# vpac_targetdb register map
Vendor: Texas Instruments
Registers are 32-bit, read-write, no defined reset value unless marked. A register's access mark holds for its fields unless they carry their own. Offsets are as the file gives them; [hi:lo] are bit positions; {n}, {i} and the like mark numbered series; 'fields as' and 'values as' point back to an identical list.

## VPAC (part 3 of 8) — Vision Pre-Processing Accelerator (VPAC)
0x44 YEE_MERGESEL — The Merge selects the output that is added to the target pixel.
  [0] yee_mergesel — The yee_mergesel selects either the sum of the LUT and edge sharpener output of the max of the absolute values from both. 0: selects the SUM. 1: elects the absolute value max.
0x44 exception_pend_clear — The Exception Logging Pending Clear Register allows to clear the pend signal.
  [0] pend_clr — Write a 1 to clear the exception pend signal.
0x44 exception_pend_clear — The Exception Logging Pending Clear Register allows to clear the pend signal.
  [0] pend_clr — Write a 1 to clear the exception pend signal.
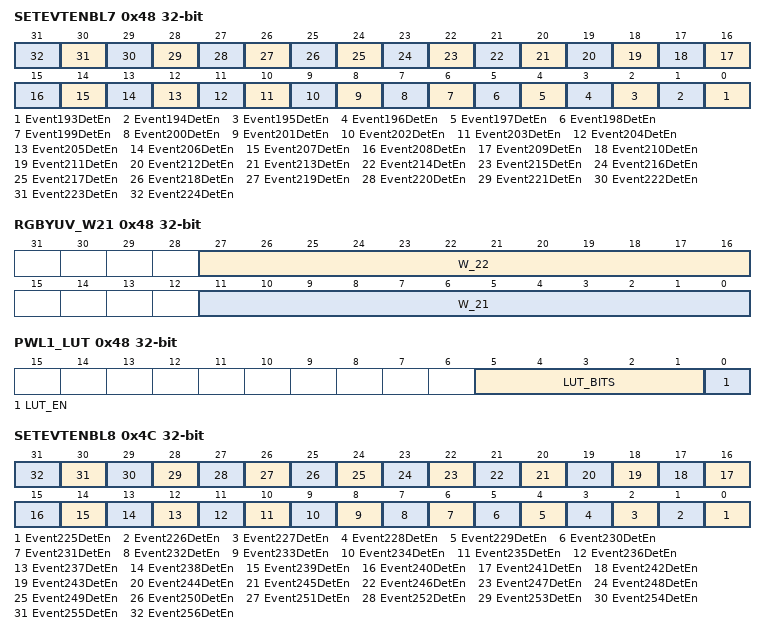
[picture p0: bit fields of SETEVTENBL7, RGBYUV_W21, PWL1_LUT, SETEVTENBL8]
0x48 SETEVTENBL7 — System event detection enable register 7 (if number of events > 192)
  [n-193] Event{n}DetEn (n=193..224) — Event({n}) Detection Enable
0x48 RD_BASE_L — Lower 32-bit of Input Frame Base Address
  [31:0] ADDR — Lower 32-bit of Read Base address of Input Frame Base Address. Must be 16-byte aligned so four LSB are coded to 0
0x48 RGBYUV_W21 access per field — Weight/Offset for Row2
  [27:16] W_22 rw — Weight W_22 : (S12 b)
  [11:0] W_21 rw — Weight W_21 : (S12 b)
0x48 PWL1_LUT access per field — Long frame PWL LUT configuration
  [5:1] LUT_BITS rw — LUT input bit depth, up to 24
  [0] LUT_EN rw — enable LUT based compression
0x48 H3A_AFCOEF1010 access per field — IIR filter coefficient data for SET 1.
  [11:0] COEFF10 rw — AF Engine IIR filter Coefficient #10 [Set 1] The range is signed -32 LTEQ value LTEQ 31 +63/64
0x48 YES_E_HAL — The Halo selects Halo reduction mode.
  [0] yes_e_hal — The yes_e_hal selects whether the 3x3 gradients is used to clip the target pixel. 0: Halo reduction off. 1: Halo reduction on.
0x4C SETEVTENBL8 — System event detection enable register 8 (if number of events > 224)
  [n-225] Event{n}DetEn (n=225..256) — Event({n}) Detection Enable
0x4C RD_420C_BASE_H — Higher 16-bit of Input Frame 420C Base Address
  [15:0] ADDR — Higher 16-bit of Input Frame Chroma Base Address in YUV420
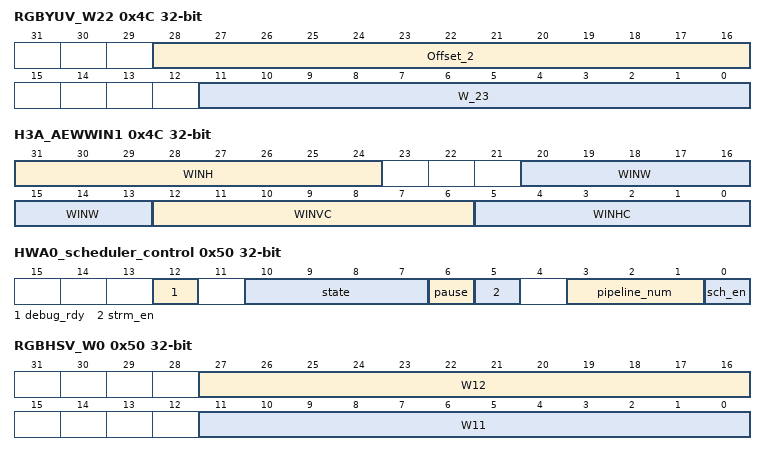
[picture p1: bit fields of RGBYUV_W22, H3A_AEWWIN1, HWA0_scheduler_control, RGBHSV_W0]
0x4C RGBYUV_W22 access per field — Weight/Offset for Row2
  [28:16] Offset_2 rw — Offset_2 : (S13b)
  [11:0] W_23 rw — Weight W_23 : (S12 b)
0x4C PWL1_LUTCLIP access per field — Long frame PWL LUT output clip value
  [15:0] LUTCLIP rw — LUT clip value
0x4C H3A_AEWWIN1 access per field — Configuration for AE/AWB Windows.
  [31:24] WINH rw — AE/AWB Engine Window Height This specifies the window height in an even number of pixels, the window height is the value plus 1 multiplied by 2 The final value can be from 2-512 [even] * This value is shadowed and latched on the rising edge of VSYNC
  [20:13] WINW rw — AE/AWB Engine Window Width This specifies the window width in an even number of pixels, the window width is the value plus 1 multiplied by 2 The minimum width is expected to be 8 pixels * This value is shadowed and latched on the rising edge of VSYNC
  [12:6] WINVC rw — AE/AWB Engine Vertical Window Count The number of windows in the vertical direction plus 1 The maximum number of vertical windows in a frame should not exceed 128 The value should be set to ensure that the bandwidth requirements and buffer size are not exceeded * This value is shadowed and latched on the rising edge of VSYNC
  [5:0] WINHC rw — AE/AWB Engine Horizontal Window Count The number of horizontal windows plus 1 The maximum number of horizontal windows is 35 plus 1 [36] The minimum number of windows should be 2 [valid range for the field is 1-35] * This value is shadowed and latched on the rising edge of VSYNC
0x4C YES_G_GAIN — The
  [7:0] yes_g_gain — The Gradient Gain
0x50 HWA0_scheduler_control access per field — Scheduler Control Register
  [12] debug_rdy rw — '0' -> HWA0 Scheduler resources must not be read during halted state. '1'-> HWA0 Scheduler resources are readable during halted state
  [10:7] state ro — Current state of HWA0 Scheduler
  [6] pause rw — '1' -> pause/suspend scheduler , '0' -> resume scheduler
  [5] strm_en rw — '1' -> Streaming input enable, '0' No streaming input
  [3:1] pipeline_num rw — Pipeline Number of HWA0 Scheduler
  [0] sch_en rw — scheduler enable; write '1' to enable scheduler
0x50 SETMSTID access per field — System Event Master ID
  [7:0] MASTID rw — HW Master ID for System Event module. Software may overwrite the value at any time, but this is only recommended for scenarios where top-level configuration errors result in a collision between HW master IDs
0x50 RD_420C_BASE_L — Lower 32-bit of Input Frame Chroma Base Address in YUV420
  [31:0] ADDR — Lower 32-bit of Read Base address of Input Frame Chroma Base Address in YUV420. Must be 16-byte aligned so four LSB are coded to 0
0x50 RGBHSV_W0 access per field — Weights 11/12 for V calculation
  [27:16] W12 rw — Weight W12 (Signed 12b)
  [11:0] W11 rw — Weight W11 (Signed 12b)
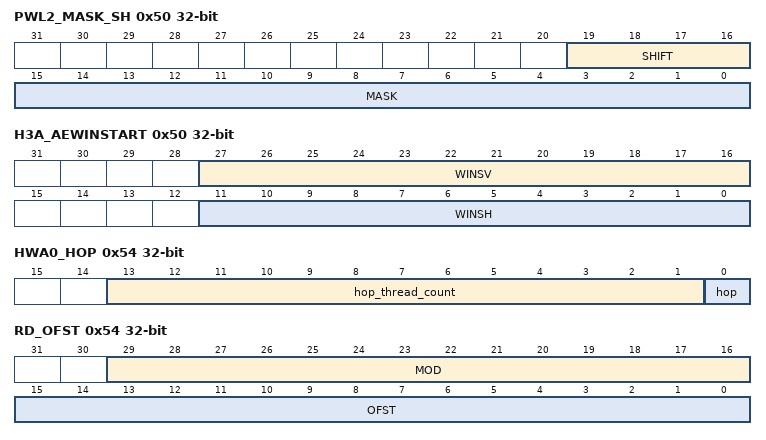
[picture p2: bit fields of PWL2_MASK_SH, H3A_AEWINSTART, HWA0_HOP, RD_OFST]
0x50 PWL2_MASK_SH access per field — Short frame PWL mask and shift values
  [19:16] SHIFT rw — number of right shift
  [15:0] MASK rw — mask bit pattern
0x50 H3A_AEWINSTART access per field — Start position for AE/AWB Windows.
  [27:16] WINSV rw — AE/AWB Engine Vertical Window Start Position Sets the first line for the first window Range 0-4095 * This value is shadowed and latched on the rising edge of VSYNC
  [11:0] WINSH rw — AE/AWB Engine Horizontal Window Start Position Sets the horizontal position for the first window on each line Range 0-4095 * This value is shadowed and latched on the rising edge of VSYNC
0x50 YES_E_GAIN — The
  [11:0] yes_e_gain — The Band-pass filter gain
0x54 HWA0_HOP — Scheduler HOP Control Register. Help in detecting eop within scheduler. Once configured, it counts task/channel starts and stops issuing further start. Specifically useful for Head of pipe dma scheduler .
  [13:1] hop_thread_count — Number of Task count for Head of pipe
  [0] hop — '1' -> Head of Pipe producer Sch , '0' -> No hop
0x54 RD_OFST — Defines the stride between rows for the Input Frame in bytes.
  [29:16] MOD — Sets the circular buffer size if circular buffering mode is used. The circular buffer is sized in terms of number of lines and has to be multiple of 2
  [15:0] OFST — Read frame line offset, must be 16-byte aligned so internally [3:0] bits are hard-wired zero. OFST is common for Luma and Chroma in YUV420 mode
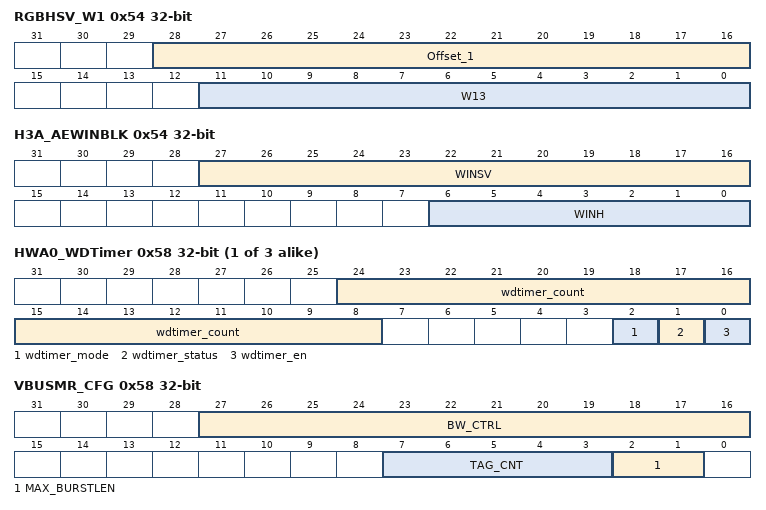
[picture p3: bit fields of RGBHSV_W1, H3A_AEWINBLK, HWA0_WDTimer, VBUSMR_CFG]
0x54 RGBHSV_W1 access per field — Weights13 and Offset_1 for V Calculation
  [28:16] Offset_1 rw — Offset_1 (Signed 13b)
  [11:0] W13 rw — Weight W13 (Signed 12b)
0x54 PWL2_EN access per field — Short frame PWL enable
  [0] ENABLE rw
0x54 H3A_AEWINBLK access per field — Start position and height for black line of AE/AWB Windows
  [27:16] WINSV rw — AE/AWB Engine Vertical Window Start Position for single black line of windows Sets the first line for the single black line of windows * This value is shadowed and latched on the rising edge of VSYNC Range 0-4095 Note that the horizontal start and the horizontal number of windows will be similar to the regular windows
  [6:0] WINH rw — AE/AWB Engine Window Height for the single black line of windows This specifies the window height in an even number of pixels, the window height is the value plus 1 multiplied by 2 The final value can be from 2-256 [even] * This value is shadowed and latched on the rising edge of VSYNC
0x54 YES_E_THR1 — The
  [15:0] yes_e_thr1 — The shrink threshold
{0x58+0xB4*i} HWA{i}_WDTimer access per field (i=0..2) — Watchdog timer control register
  [24:8] wdtimer_count ro — Current value of HWA{i} Scheduler watchdog timer count
  [2] wdtimer_mode rw — Watchdog timeout count '1' -> 128K , '0' -> 64K
  [1] wdtimer_status ro — HWA{i} Scheduler watchdog timer status '1' -> Timer Active '0' -> Timer Inactive (count is stable)
  [0] wdtimer_en rw — '1' -> activate watchdog timer for 64K VPAC/DMPAC cycles between task start and task done '0' -> Disable watchdog timer
0x58 VBUSMR_CFG — Control VBUSM Read Interface
  [27:16] BW_CTRL — Limits the mean bandwidth (computed over one block) that the LDC module can request for read from system memory. 0: The BW limiter is bypassed 1~4095: maximum number of bytes per cycle multiplied by 2^8. Examples: 1 : 1.17 MBytes/s @ 300 MHz 4095 : ~4.8 GBytes/s @ 300 Mhz
  [7:3] TAG_CNT — Limits the maximum number of outstanding LDC requests to TAG_CNT+1
  [2:1] MAX_BURSTLEN — Limits the maximum burst length that could be used by LDC. Each burst is of 16 bytes. HW also breaks the command at max burst size boundary. For K3 devices, it is best to keep burst size of 8 which command size of 128 bytes. 0: 16 1: 8 2: 4 3: 2
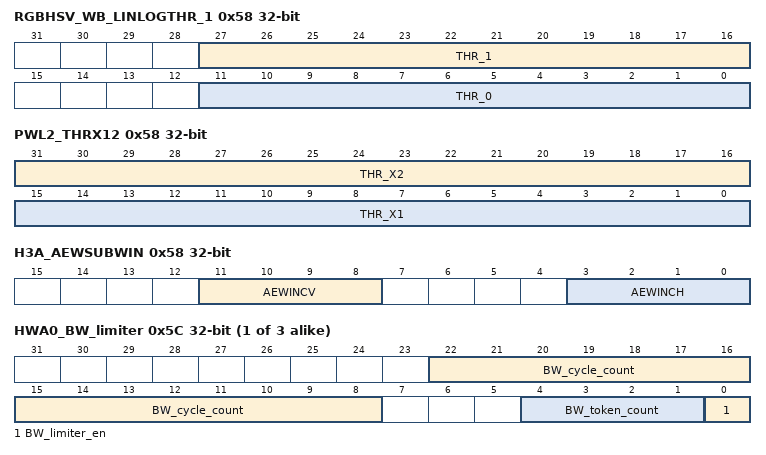
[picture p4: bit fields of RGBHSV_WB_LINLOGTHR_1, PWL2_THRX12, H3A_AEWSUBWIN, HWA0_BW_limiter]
0x58 RGBHSV_WB_LINLOGTHR_1 access per field — Dynamic WB Thr limit
  [27:16] THR_1 rw — THR_1 / G-Channel Thr (U 12b)
  [11:0] THR_0 rw — THR_0 / R-Channel Thr (U 12b)
0x58 PWL2_THRX12 — Short frame PWL threshold X1 and X2 - Unsigned
  [31:16] THR_X2 — threshold X2
  [15:0] THR_X1 — threshold X1
0x58 H3A_AEWSUBWIN access per field — Configuration for subsample data in AE/AWB window.
  [11:8] AEWINCV rw — AE/AWB Engine Vertical Sampling Point Increment Sets vertical distance between sub-samples within a window plus 1 multiplied by 2 The final range is 2-32 * This value is shadowed and latched on the rising edge of VSYNC
  [3:0] AEWINCH rw — AE/AWB Engine Horizontal Sampling Point Increment Sets horizontal distance between sub-samples within a window plus 1 multiplied by 2 The final range is 2-32 * This value is shadowed and latched on the rising edge of VSYNC
0x58 YES_E_THR2 — The
  [9:0] yes_e_thr2 — The clip threshold
{0x5C+0xB4*i} HWA{i}_BW_limiter (i=0..2) — Scheduler BW Control Register. Processing unit level BW control. Use DMA to eliminate peak system BW within processing units line/Block
  [22:8] BW_cycle_count — Average Cycle count between successive Task Start
  [4:1] BW_token_count — Max Token count to create average BW
  [0] BW_limiter_en — '1' -> Enable BW limiter function for HWA{i} sch, '0' --> Disable
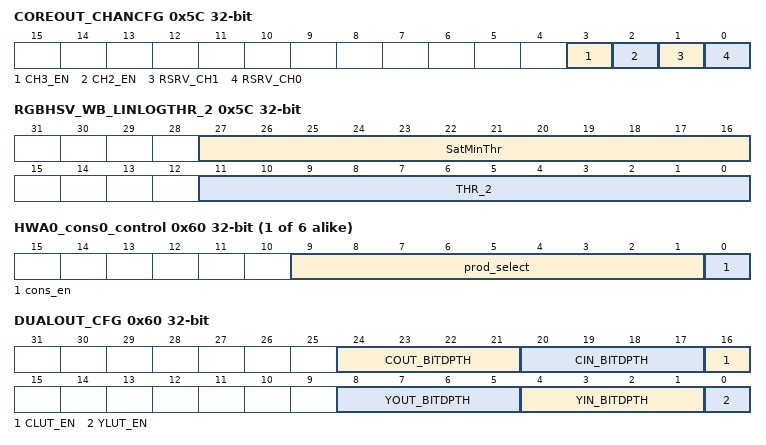
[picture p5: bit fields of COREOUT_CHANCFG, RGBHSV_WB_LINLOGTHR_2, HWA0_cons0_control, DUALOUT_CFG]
0x5C COREOUT_CHANCFG access per field — LDC Core to LSE output channel enable control
  [3] CH3_EN rw — Enable for LDC Core to LSE Channel_3 connection used for Chroma Dual output
  [2] CH2_EN rw — Enable for LDC Core to LSE Channel_2 connection used for Luma Dual output
  [1] RSRV_CH1 ro — Primary Chroma channel (LSE Channel_1) enable extracted from output data mode
  [0] RSRV_CH0 ro — Primary Luuma channel (LSE Channel_0) enable extracted from output data mode
0x5C RGBHSV_WB_LINLOGTHR_2 access per field — Dynamic WB Thr limit and SatMinThr
  [27:16] SatMinThr rw — Thr for comparing Min(RGB) limit
  [11:0] THR_2 rw — THR_2 / B-Channel Thr (U 12b)
0x5C PWL2_THRX3 access per field — Short frame PWL threshold X3 - Unsigned
  [15:0] THR_X3 rw — threshold X3
0x5C H3A_AEWBUFST access per field — SDRAM destination address for AE/AWB engine statistics
  [31:5] AEWBUFST rw — SDRAM destination address for AE/AWB engine statistics The start location in SDRAM for the AE/AWB statistics The 6 LSB are ignored, address should be on a 64-byte boundary This field can be altered even when the AE/AWB is busy Change will take place only for the next frame However, note that reading this register will always give the latest value
0x5C YES_G_OFT — The
  [9:0] yes_g_oft — The offset applied to the Gradient gain
{0x60+4i} HWA0_cons{i}_control (i=0..5) — Controlling consumer socket {i} for HWA0
  [9:1] prod_select — producer select for HWA0 cons socket {i}
  [0] cons_en — '1' -> Consumer socket {i} enable , '0' Disable
0x60 DUALOUT_CFG — Configuration for Dual Luma and Chroma channels and LUT
  [24:21] COUT_BITDPTH — Chroma Output Data Bit depth. Output clipped at 2^COUT_BITDPTH -1. Valid values 12-8
  [20:17] CIN_BITDPTH — Chroma Input Data Bit depth. Should same as YIN_BITDPTH. Valid values 12 to 8
  [16] CLUT_EN — Chroma LUT mapping enable. If disabled data is sent as it is bypassing LUT mapping
  [8:5] YOUT_BITDPTH — Luma Output Data Bit depth. Output clipped at 2^YOUT_BITDPTH -1. Valid values 12-8
  [4:1] YIN_BITDPTH — Luma Input Data Bit depth. Valid values 12 to 8
  [0] YLUT_EN — Luma LUT mapping enable. If disabled data is sent as it is bypassing LUT mapping
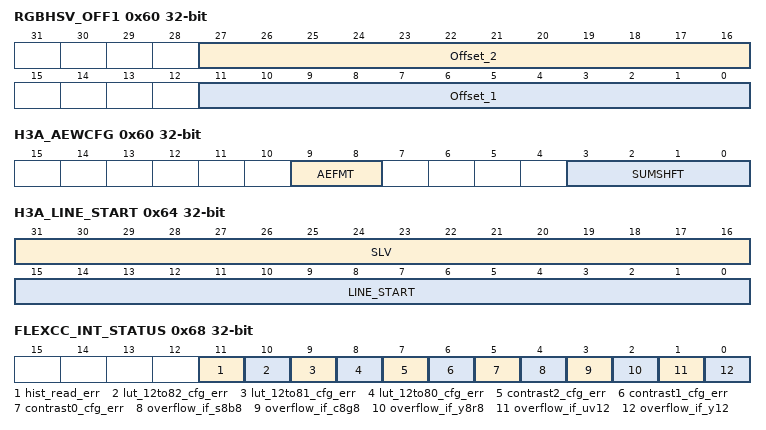
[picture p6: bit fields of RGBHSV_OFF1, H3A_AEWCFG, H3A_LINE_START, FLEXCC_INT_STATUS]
0x60 RGBHSV_OFF1 access per field — WB Offset for Saturation
  [27:16] Offset_2 rw — Offset_2 (U 12b)
  [11:0] Offset_1 rw — Offset-1 (U 12b)
{0x5C+4i} PWL2_THRY{i} access per field (i=1..3) — Short frame PWL threshold Y{i} - Unsigned
  [23:0] THR_Y{i} rw — threshold Y{i}
0x60 H3A_AEWCFG access per field — Configuration for AE/AWB
  [9:8] AEFMT rw — AE/AWB output format 0 = sum of squares 1 = min/max 2 = sum only; no sum of squares or min/max * This value is shadowed and latched on the rising edge of VSYNC
  [3:0] SUMSHFT rw — AE/AWB engine shift value for the accumulation of pixel values This bitfield sets the right shift value which is applied on the result of the pixel accumulation before it is stored in the packet The accumulation takes place on 26 bits which is enough for 10-bit data and a maximum widow size of 512 x 512 which results into the accumulation of 256 x 256 pixels of the same color The shift value shall be set such that the result fits on 16 bits SUMSHFT = right shift value Range: 0 -15 * This value is shadowed and latched on the rising edge of VSYNC
0x64 RGBHSV_OFF2 access per field — WB Offsets for Saturation
  [11:0] Offset_3 rw — Offset-3 (U 12b)
0x64 H3A_LINE_START — Line Framing Logic Register In certain cases the number of clock cycles between HD pulses will be greater than the line buffer included in the H3A module. The framing module prior to the line buffer enables to control the data which is input to the line buffer.
  [31:16] SLV — Start Line Vertical Specifies how many lines after the VD rising edge the real frame starts
  [15:0] LINE_START — Line Start The framing module uses the LINE_START bitfield to find the position of the first pixel to place into the line buffer Range: 0-65535
0x68 FLEXCC_INT_STATUS access per field — Status/clear register for flexcc interrupts
  [11] hist_read_err rw — status/clear for histogram memory, set when mem access has occurred to the first location but not to the last location during active frame implying that full histogram was not read . Write 1 to clear, write 0 has no effect
  [10] lut_12to82_cfg_err rw — status/clear for 12to8_2_lut cfg err, set when mem access occurs during active line when the LUT is enabled causing frame corruption. Write 1 to clear, write 0 has no effect
  [9] lut_12to81_cfg_err rw — status/clear for 12to8_1_lut cfg err, set when mem access occurs during active line when the LUT is enabled causing frame corruption. Write 1 to clear, write 0 has no effect
  [8] lut_12to80_cfg_err rw — status/clear for 12to8_0_lut cfg err, set when mem access occurs during active line when the LUT is enabled causing frame corruption. Write 1 to clear, write 0 has no effect
  [7] contrast2_cfg_err rw — status/clear for contrast2_lut cfg err, set when mem access occurs during active line when the LUT is enabled causing frame corruption. Write 1 to clear, write 0 has no effect
  [6] contrast1_cfg_err rw — status/clear for contrast1_lut cfg err, set when mem access occurs during active line when the LUT is enabled causing frame corruption. Write 1 to clear, write 0 has no effect
  [5] contrast0_cfg_err rw — status/clear for contrast0_lut cfg err, set when mem access occurs during active line when the LUT is enabled causing frame corruption. Write 1 to clear, write 0 has no effect
  [4] overflow_if_s8b8 rw — status/clear for overflow on s8b8 i/f, set when fifo overflows causing frame corruption. Write 1 to clear, write 0 has no effect
  [3] overflow_if_c8g8 rw — status/clear for overflow on c8g8 i/f, set when fifo overflows causing frame corruption. Write 1 to clear, write 0 has no effect
  [2] overflow_if_y8r8 rw — status/clear for overflow on y8r8 i/f, set when fifo overflows causing frame corruption. Write 1 to clear, write 0 has no effect
  [1] overflow_if_uv12 rw — status/clear for overflow on uv12 i/f, set when fifo overflows causing frame corruption. Write 1 to clear, write 0 has no effect
  [0] overflow_if_y12 rw — status/clear for overflow on y12 i/f, set when fifo overflows causing frame corruption. Write 1 to clear, write 0 has no effect
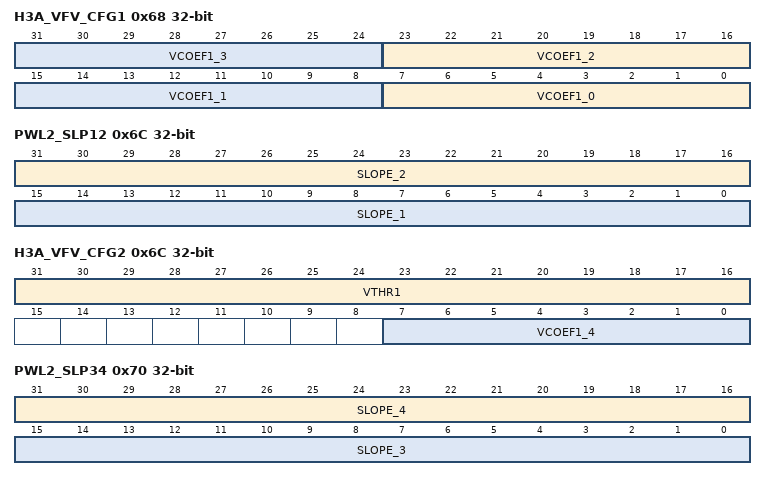
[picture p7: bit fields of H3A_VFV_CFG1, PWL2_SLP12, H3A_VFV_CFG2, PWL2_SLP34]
0x68 H3A_VFV_CFG1 — Vertical focus value configuration 1.
  [8n+7:8n] VCOEF1_{n} (n=0..3) — Vertical FV FIR 1 coefficient {n}
0x6C PWL2_SLP12 — Short frame PWL slope 1 and 2 - Unsigned
  [31:16] SLOPE_2, [15:0] SLOPE_1
0x6C H3A_VFV_CFG2 access per field — Vertical focus value configuration 2.
  [31:16] VTHR1 rw — Threshold for vertical FV FIR 1
  [7:0] VCOEF1_4 rw — Vertical FV FIR 1 coefficient 4
0x70 PWL2_SLP34 — Short frame PWL slope 3 and 4 - Unsigned
  [31:16] SLOPE_4, [15:0] SLOPE_3
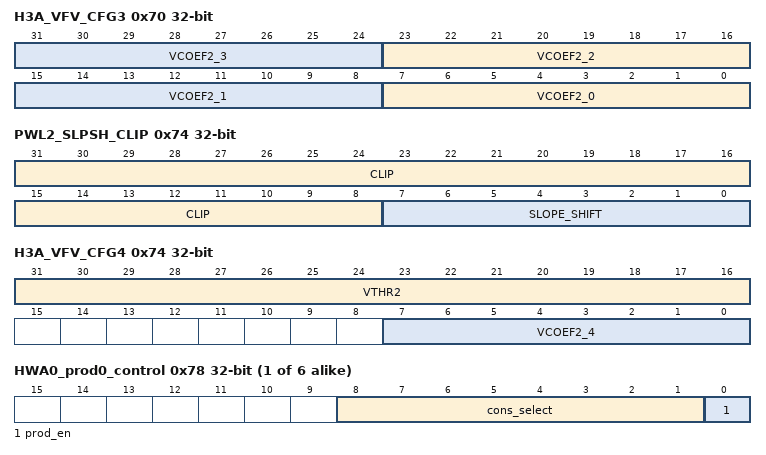
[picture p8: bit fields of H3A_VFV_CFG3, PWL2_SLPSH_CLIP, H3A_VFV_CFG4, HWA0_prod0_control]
0x70 H3A_VFV_CFG3 — Vertical focus value configuration 4.
  [8n+7:8n] VCOEF2_{n} (n=0..3) — Vertical FV FIR 2 coefficient {n}
0x74 PWL2_SLPSH_CLIP — Short frame PWL slope shift and clip
  [31:8] CLIP — clip value
  [7:0] SLOPE_SHIFT — shift value for slope, must not exceed decimal 33
0x74 H3A_VFV_CFG4 access per field — Vertical focus value configuration 4.
  [31:16] VTHR2 rw — Threshold for vertical FV FIR 2
  [7:0] VCOEF2_4 rw — Vertical FV FIR 2 coefficient 4
{0x78+0x14*i} HWA0_prod{i}_control (i=0..5) — Controlling producer socket{i} for HWA0
  [8:1] cons_select — consumer select for HWA0 prod socket {i}. Used in decrementing count of producer buffer
  [0] prod_en — '1' -> Producer socket 0 enable , '0' Disable
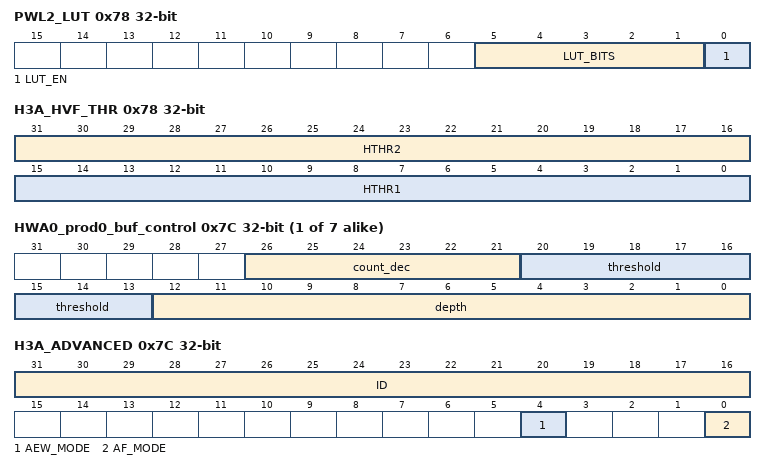
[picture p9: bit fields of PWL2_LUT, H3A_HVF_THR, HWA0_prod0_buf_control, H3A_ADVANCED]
0x78 PWL2_LUT access per field — Short frame PWL LUT configuration
  fields as PWL1_LUT
0x78 H3A_HVF_THR — Horizontal Focus Value Threshold
  [31:16] HTHR2 — Threshold for horizontal FV IIR 2
  [15:0] HTHR1 — Threshold for horizontal FV IIR 1
{0x7C+0x14*i} HWA0_prod{i}_buf_control (i=0..6) — Controlling producer socket{i} buffer for HWA0
  [26:21] count_dec — Count decrement value for prod count
  [20:13] threshold — Count threshold to generate pend for consumer
  [12:0] depth — Maximum number of producer buffer count
0x7C PWL2_LUTCLIP access per field — Short frame PWL LUT output clip value
  [15:0] LUTCLIP rw — LUT clip value
0x7C H3A_ADVANCED access per field — advanced setting register, NOT FOR TRM
  [31:16] ID ro — Below information should not be in TRM To access the other bitfields [AF_MODE/AEW_MODE], certain value should be written to this ID field first First, the ID is written to this field Second, the AF_MODE or/and AEW_MODE is written
  [4] AEW_MODE rw — This bit should not be included in TRM This bit is accesible only if ID is set to 0xDC00 AE/AWB engine custom mode [AVE2 mode] select
  [0] AF_MODE rw — AF engine mode Below information should not be included in TRM The effect of this bit changes based on the ID value If other value than 0xCA00 or 0xDC00 is set to ID, this field has no effect
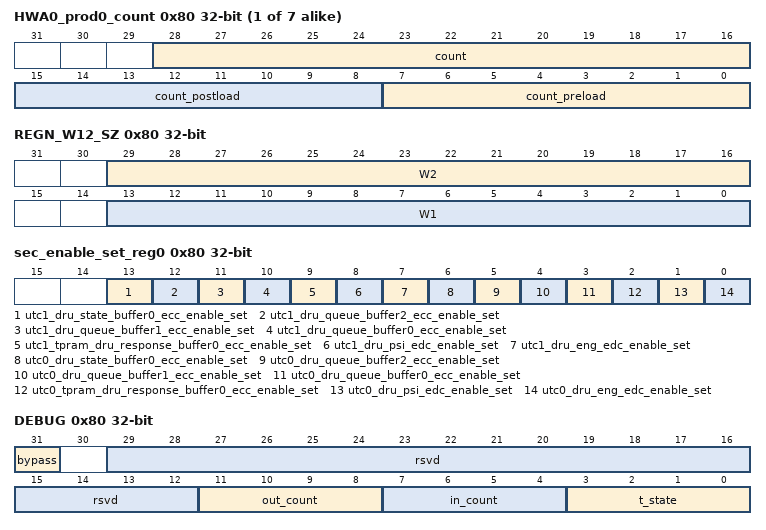
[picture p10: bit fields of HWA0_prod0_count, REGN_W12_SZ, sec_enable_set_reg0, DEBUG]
{0x80+0x14*i} HWA0_prod{i}_count access per field (i=0..6) — Defining count values for pre/post load for generating pend by HWA0 prod{i}
  [28:16] count ro — current count value
  [15:8] count_postload rw — count postload after producer max thread count reached
  [7:0] count_preload rw — count preload after scheduler start/init
0x80 sec_enable_set_reg0 — Interrupt Enable Set Register 0
  [13] utc1_dru_state_buffer0_ecc_enable_set — Interrupt Enable Set Register for utc1_dru_state_buffer0_ecc_pend
  [12] utc1_dru_queue_buffer2_ecc_enable_set — Interrupt Enable Set Register for utc1_dru_queue_buffer2_ecc_pend
  [11] utc1_dru_queue_buffer1_ecc_enable_set — Interrupt Enable Set Register for utc1_dru_queue_buffer1_ecc_pend
  [10] utc1_dru_queue_buffer0_ecc_enable_set — Interrupt Enable Set Register for utc1_dru_queue_buffer0_ecc_pend
  [9] utc1_tpram_dru_response_buffer0_ecc_enable_set — Interrupt Enable Set Register for utc1_tpram_dru_response_buffer0_ecc_pend
  [8] utc1_dru_psi_edc_enable_set — Interrupt Enable Set Register for utc1_dru_psi_edc_pend
  [7] utc1_dru_eng_edc_enable_set — Interrupt Enable Set Register for utc1_dru_eng_edc_pend
  [6] utc0_dru_state_buffer0_ecc_enable_set — Interrupt Enable Set Register for utc0_dru_state_buffer0_ecc_pend
  [5] utc0_dru_queue_buffer2_ecc_enable_set — Interrupt Enable Set Register for utc0_dru_queue_buffer2_ecc_pend
  [4] utc0_dru_queue_buffer1_ecc_enable_set — Interrupt Enable Set Register for utc0_dru_queue_buffer1_ecc_pend
  [3] utc0_dru_queue_buffer0_ecc_enable_set — Interrupt Enable Set Register for utc0_dru_queue_buffer0_ecc_pend
  [2] utc0_tpram_dru_response_buffer0_ecc_enable_set — Interrupt Enable Set Register for utc0_tpram_dru_response_buffer0_ecc_pend
  [1] utc0_dru_psi_edc_enable_set — Interrupt Enable Set Register for utc0_dru_psi_edc_pend
  [0] utc0_dru_eng_edc_enable_set — Interrupt Enable Set Register for utc0_dru_eng_edc_pend
0x80 sec_enable_set_reg0 — Interrupt Enable Set Register 0
  [n+8] meshmem_b{n}_p1_ramecc_enable_set (n=0..3) — Interrupt Enable Set Register for meshmem_b{n}_p1_ramecc_pend
  [n+4] meshmem_b{n}_p0_ramecc_enable_set (n=0..3) — Interrupt Enable Set Register for meshmem_b{n}_p0_ramecc_pend
  [3] dualc_lut_b1_ramecc_enable_set — Interrupt Enable Set Register for dualc_lut_b1_ramecc_pend
  [2] dualc_lut_b0_ramecc_enable_set — Interrupt Enable Set Register for dualc_lut_b0_ramecc_pend
  [1] dualy_lut_b1_ramecc_enable_set — Interrupt Enable Set Register for dualy_lut_b1_ramecc_pend
  [0] dualy_lut_b0_ramecc_enable_set — Interrupt Enable Set Register for dualy_lut_b0_ramecc_pend
0x80 REGN_W12_SZ — Horizontal slice width for Region division
  [29:16] W2 — Width of second horizontal slice. (Minium of 8 and must be even)
  [13:0] W1 — Width of first horizontal slice. (Minium of 8 and must be even)
0x80 sec_enable_set_reg0 — Interrupt Enable Set Register 0
  [31] fcc_lut1_ram1_ramecc_enable_set — Interrupt Enable Set Register for fcc_lut1_ram1_ramecc_pend
  [30] fcc_lut1_ram0_ramecc_enable_set — Interrupt Enable Set Register for fcc_lut1_ram0_ramecc_pend
  [29] fcc_lut0_ram1_ramecc_enable_set — Interrupt Enable Set Register for fcc_lut0_ram1_ramecc_pend
  [28] fcc_lut0_ram0_ramecc_enable_set — Interrupt Enable Set Register for fcc_lut0_ram0_ramecc_pend
  [27] fcc_cont_lut3_ram1_ramecc_enable_set — Interrupt Enable Set Register for fcc_cont_lut3_ram1_ramecc_pend
  [26] fcc_cont_lut3_ram0_ramecc_enable_set — Interrupt Enable Set Register for fcc_cont_lut3_ram0_ramecc_pend
  [25] fcc_cont_lut2_ram1_ramecc_enable_set — Interrupt Enable Set Register for fcc_cont_lut2_ram1_ramecc_pend
  [24] fcc_cont_lut2_ram0_ramecc_enable_set — Interrupt Enable Set Register for fcc_cont_lut2_ram0_ramecc_pend
  [23] fcc_cont_lut1_ram1_ramecc_enable_set — Interrupt Enable Set Register for fcc_cont_lut1_ram1_ramecc_pend
  [22] fcc_cont_lut1_ram0_ramecc_enable_set — Interrupt Enable Set Register for fcc_cont_lut1_ram0_ramecc_pend
  [21] fcc_hist_ram1_ramecc_enable_set — Interrupt Enable Set Register for fcc_hist_ram1_ramecc_pend
  [20] fcc_hist_ram0_ramecc_enable_set — Interrupt Enable Set Register for fcc_hist_ram0_ramecc_pend
  [n+12] stat_mem{n}_ramecc_enable_set (n=0..7) — Interrupt Enable Set Register for stat_mem{n}_ramecc_pend
  [11] h3a_lut_ram1_ramecc_enable_set — Interrupt Enable Set Register for h3a_lut_ram1_ramecc_pend
  [10] h3a_lut_ram0_ramecc_enable_set — Interrupt Enable Set Register for h3a_lut_ram0_ramecc_pend
  [9] lsc_ramecc_enable_set — Interrupt Enable Set Register for lsc_ramecc_pend
  [8] dpc_lut_ramecc_enable_set — Interrupt Enable Set Register for dpc_lut_ramecc_pend
  [7] wdr_lut_ram1_ramecc_enable_set — Interrupt Enable Set Register for wdr_lut_ram1_ramecc_pend
  [6] wdr_lut_ram0_ramecc_enable_set — Interrupt Enable Set Register for wdr_lut_ram0_ramecc_pend
  [5] lut1_ram1_ramecc_enable_set — Interrupt Enable Set Register for lut1_ram1_ramecc_pend
  [4] lut1_ram0_ramecc_enable_set — Interrupt Enable Set Register for lut1_ram0_ramecc_pend
  [3] lut2_ram1_ramecc_enable_set — Interrupt Enable Set Register for lut2_ram1_ramecc_pend
  [2] lut2_ram0_ramecc_enable_set — Interrupt Enable Set Register for lut2_ram0_ramecc_pend
  [1] lut3_ram1_ramecc_enable_set — Interrupt Enable Set Register for lut3_ram1_ramecc_pend
  [0] lut3_ram0_ramecc_enable_set — Interrupt Enable Set Register for lut3_ram0_ramecc_pend
0x80 VISS_DBG_CTL — Enable for VISS debug staus capture
  [1] PRTL_WR_EN — Enable to Capture Partial Write to any VISS end point
0x80 PWL2_OFF1 access per field — Short frame WB Offset 1
  [23:0] OFST00 rw — S24, WB Offset at pixel 00
0x80 DEBUG access per field
  [31] bypass rw — Bypass Mode When enabled output equals the input , namely C2_R0 input matrix
  [29:12] rsvd ro — Always read as 0. Writes have no affect
  [11:8] out_count ro — output free running counter , gets reset on start of line
  [7:4] in_count ro — input free running counter , gets reset on start of line
  [3:0] t_state ro — StateMachine State
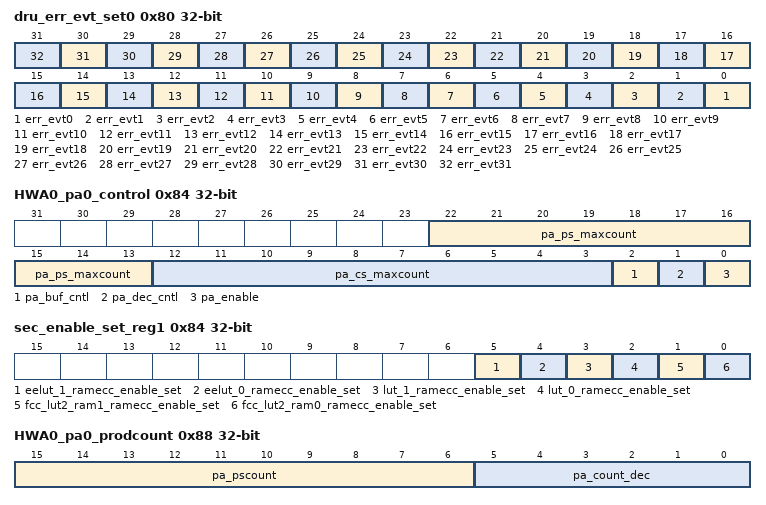
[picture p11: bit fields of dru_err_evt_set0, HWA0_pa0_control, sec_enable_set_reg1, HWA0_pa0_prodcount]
0x80 dru_err_evt_set0 wo — DRU Error Event Set Register
  [n] err_evt{n} (n=0..31) — Set the Error Event for channel {n}
0x80 dru_err_evt_set0 wo — DRU Error Event Set Register
  [n] err_evt{n} (n=0..63) — Set the Error Event for channel {n}
0x84 HWA0_pa0_control — control register to manage pattern adapter on HWA0 prod socket0
  [22:13] pa_ps_maxcount — destination count for pattern adaptation (N), M --> N
  [12:3] pa_cs_maxcount — source count for pattern adaptation (M), M --> N
  [2] pa_buf_cntl — '1' -> Apply threshold, count_preload and count_postload on pattern adapter count (use this only when pa_enable='1') '0' -> Apply threshold, count_preload and count_postload on prod count (same behavior as if no pattern adapter. Note when pa_enable='1' and pa_buf_cntl='0' threshold is not used and ignored)
  [1] pa_dec_cntl — '1' -> post pattern adaptation, decrement ps count by count_dec , '0' -> post pattern adaptation, decrement ps count by pa_cs_maxcount
  [0] pa_enable — '1' -> pa enable, '0' -> disable
0x84 REGN_W3_SZ — Horizontal slice width for Region division
  [13:0] W3 — Width of third horizontal slice. (Minium of 8 and must be even)
0x84 sec_enable_set_reg1 — Interrupt Enable Set Register 1
  [5] eelut_1_ramecc_enable_set — Interrupt Enable Set Register for eelut_1_ramecc_pend
  [4] eelut_0_ramecc_enable_set — Interrupt Enable Set Register for eelut_0_ramecc_pend
  [3] lut_1_ramecc_enable_set — Interrupt Enable Set Register for lut_1_ramecc_pend
  [2] lut_0_ramecc_enable_set — Interrupt Enable Set Register for lut_0_ramecc_pend
  [1] fcc_lut2_ram1_ramecc_enable_set — Interrupt Enable Set Register for fcc_lut2_ram1_ramecc_pend
  [0] fcc_lut2_ram0_ramecc_enable_set — Interrupt Enable Set Register for fcc_lut2_ram0_ramecc_pend
0x84 VISS_DBG_STAT — Set/Clear for VISS debug status
  [1] PRTL_WR — Status/Clear for Partial Write to any VISS end point. Set on Partial Write at VISS_Top input Cfg interface
0x84 PWL2_OFF2 access per field — Short frame Offset 2
  [23:0] OFST01 rw — S24, Offset at pixel 01
0x88 HWA0_pa0_prodcount access per field — count values for HWA0 prod socket0
  [15:6] pa_pscount ro — current count value of pa prod count
  [5:0] pa_count_dec rw — Decrement count value of pa_prod_count after pattern adapter prod count reaches threshold
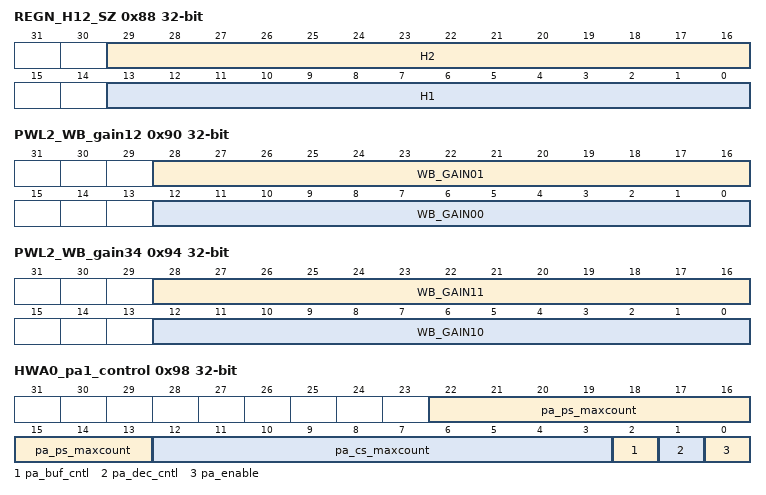
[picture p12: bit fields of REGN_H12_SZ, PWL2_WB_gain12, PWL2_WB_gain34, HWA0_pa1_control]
0x88 REGN_H12_SZ — vertical slice height for Region division
  [29:16] H2 — Height of second vertical slice. (must be even)
  [13:0] H1 — Height of first vertical slice. (must be even)
0x88 PWL2_OFF3 access per field — Short frame Offset 3
  [23:0] OFST10 rw — S24, Offset at pixel 10
0x8C REGN_H3_SZ — vertical slice height for Region division
  [13:0] H3 — Height of third vertical slice. (must be even)
0x8C PWL2_OFF4 access per field — Short frame Offset 4
  [23:0] OFST11 rw — S24, Offset at pixel 11
0x90 PWL2_WB_gain12 access per field — Short Frame white balance gain 1 and 2
  [28:16] WB_GAIN01 rw — U13Q9, WB gain at pixel 01
  [12:0] WB_GAIN00 rw — U13Q9, WB gain at pixel 00
0x94 PWL2_WB_gain34 access per field — Short Frame white balance gain 3 and 4
  [28:16] WB_GAIN11 rw — U13Q9, WB gain at pixel 11
  [12:0] WB_GAIN10 rw — U13Q9, WB gain at pixel 10
0x98 HWA0_pa1_control — control register to manage pattern adapter on HWA0 prod socket1
  fields as HWA0_pa0_control
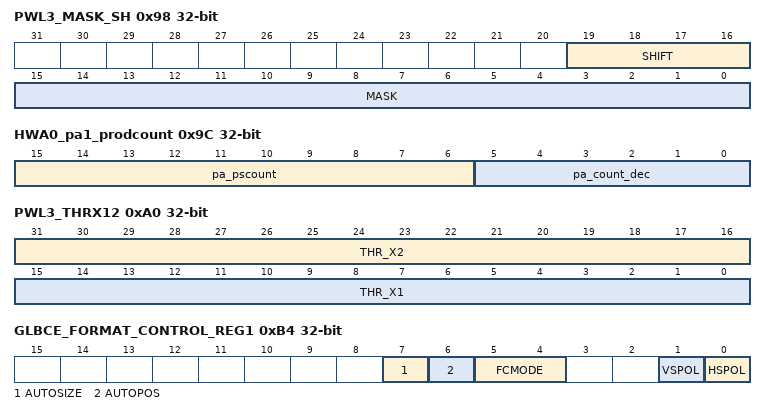
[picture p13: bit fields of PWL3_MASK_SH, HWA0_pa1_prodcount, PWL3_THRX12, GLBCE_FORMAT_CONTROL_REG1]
0x98 PWL3_MASK_SH access per field — Very short frame PWL mask and shift values
  fields as PWL2_MASK_SH
0x9C HWA0_pa1_prodcount access per field — count values for HWA0 prod socket1
  fields as HWA0_pa0_prodcount
0x9C PWL3_EN access per field — Very short frame PWL enable
  [0] ENABLE rw
0xA0 PWL3_THRX12 — Very short frame PWL threshold X1 and X2 - Unsigned
  [31:16] THR_X2 — threshold X2
  [15:0] THR_X1 — threshold X1
0xA4 PWL3_THRX3 access per field — Very short frame PWL threshold X3 - Unsigned
  [15:0] THR_X3 rw — threshold X3
{0xA4+4i} PWL3_THRY{i} access per field (i=1..3) — Very short frame PWL threshold Y{i} - Unsigned
  [23:0] THR_Y{i} rw — threshold Y{i}
0xB0 GLBCE_FORMAT_CONTROL_REG0 ro — Data format port specifies the input data format so that the GLBCE core can process the different input data formats. This register is reserved for this version of HW
  [1:0] DATAFORMAT — This value is reserved The color format is always RGB, and this value should be fixed 0
0xB4 GLBCE_FORMAT_CONTROL_REG1 ro — Control Reg1
  [7] AUTOSIZE — This value is read only. GLBCE in this HW version never use Auto-size mode
  [6] AUTOPOS — This value is read only. GLBCE in this HW version always runs in Auto Position mode
  [5:4] FCMODE — Field Correction Mode
  [1] VSPOL — Vertical Sync Polarity This value is read only The SWITCH block always convert the polarity to rising edge active
  [0] HSPOL — Horizontal Sync Polarity This value is read only The SWITCH block always convert the polarity to rising edge active
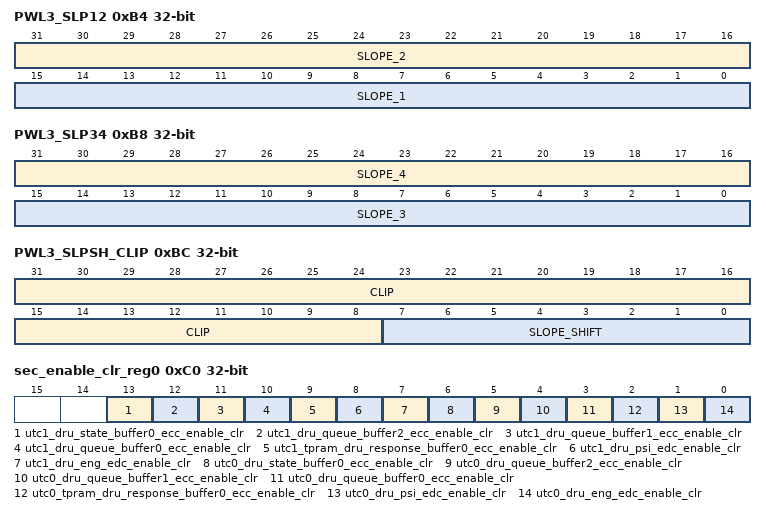
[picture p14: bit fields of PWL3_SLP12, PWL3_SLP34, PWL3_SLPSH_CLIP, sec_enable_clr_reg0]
0xB4 PWL3_SLP12 — Very short frame PWL slope 1 and 2 - Unsigned
  [31:16] SLOPE_2, [15:0] SLOPE_1
0xB8 GLBCE_FRAME_WIDTH access per field — Frame Width is the number of pixels in an active line. This port is used only in non-automatic mode.
  [15:0] VAL rw — Frame Width. minimum of 480
0xB8 PWL3_SLP34 — Very short frame PWL slope 3 and 4 - Unsigned
  [31:16] SLOPE_4, [15:0] SLOPE_3
0xBC GLBCE_FRAME_HEIGHT access per field — Frame Height is the number of active lines in one field.
  [15:0] VAL rw — Frame Height. minimum of 240
0xBC PWL3_SLPSH_CLIP — Very short frame PWL slope shift and clip
  fields as PWL2_SLPSH_CLIP
0xC0 sec_enable_clr_reg0 — Interrupt Enable Clear Register 0
  [13] utc1_dru_state_buffer0_ecc_enable_clr — Interrupt Enable Clear Register for utc1_dru_state_buffer0_ecc_pend
  [12] utc1_dru_queue_buffer2_ecc_enable_clr — Interrupt Enable Clear Register for utc1_dru_queue_buffer2_ecc_pend
  [11] utc1_dru_queue_buffer1_ecc_enable_clr — Interrupt Enable Clear Register for utc1_dru_queue_buffer1_ecc_pend
  [10] utc1_dru_queue_buffer0_ecc_enable_clr — Interrupt Enable Clear Register for utc1_dru_queue_buffer0_ecc_pend
  [9] utc1_tpram_dru_response_buffer0_ecc_enable_clr — Interrupt Enable Clear Register for utc1_tpram_dru_response_buffer0_ecc_pend
  [8] utc1_dru_psi_edc_enable_clr — Interrupt Enable Clear Register for utc1_dru_psi_edc_pend
  [7] utc1_dru_eng_edc_enable_clr — Interrupt Enable Clear Register for utc1_dru_eng_edc_pend
  [6] utc0_dru_state_buffer0_ecc_enable_clr — Interrupt Enable Clear Register for utc0_dru_state_buffer0_ecc_pend
  [5] utc0_dru_queue_buffer2_ecc_enable_clr — Interrupt Enable Clear Register for utc0_dru_queue_buffer2_ecc_pend
  [4] utc0_dru_queue_buffer1_ecc_enable_clr — Interrupt Enable Clear Register for utc0_dru_queue_buffer1_ecc_pend
  [3] utc0_dru_queue_buffer0_ecc_enable_clr — Interrupt Enable Clear Register for utc0_dru_queue_buffer0_ecc_pend
  [2] utc0_tpram_dru_response_buffer0_ecc_enable_clr — Interrupt Enable Clear Register for utc0_tpram_dru_response_buffer0_ecc_pend
  [1] utc0_dru_psi_edc_enable_clr — Interrupt Enable Clear Register for utc0_dru_psi_edc_pend
  [0] utc0_dru_eng_edc_enable_clr — Interrupt Enable Clear Register for utc0_dru_eng_edc_pend
0xC0 sec_enable_clr_reg0 — Interrupt Enable Clear Register 0
  [n+8] meshmem_b{n}_p1_ramecc_enable_clr (n=0..3) — Interrupt Enable Clear Register for meshmem_b{n}_p1_ramecc_pend
  [n+4] meshmem_b{n}_p0_ramecc_enable_clr (n=0..3) — Interrupt Enable Clear Register for meshmem_b{n}_p0_ramecc_pend
  [3] dualc_lut_b1_ramecc_enable_clr — Interrupt Enable Clear Register for dualc_lut_b1_ramecc_pend
  [2] dualc_lut_b0_ramecc_enable_clr — Interrupt Enable Clear Register for dualc_lut_b0_ramecc_pend
  [1] dualy_lut_b1_ramecc_enable_clr — Interrupt Enable Clear Register for dualy_lut_b1_ramecc_pend
  [0] dualy_lut_b0_ramecc_enable_clr — Interrupt Enable Clear Register for dualy_lut_b0_ramecc_pend
0xC0 sec_enable_clr_reg0 — Interrupt Enable Clear Register 0
  [31] fcc_lut1_ram1_ramecc_enable_clr — Interrupt Enable Clear Register for fcc_lut1_ram1_ramecc_pend
  [30] fcc_lut1_ram0_ramecc_enable_clr — Interrupt Enable Clear Register for fcc_lut1_ram0_ramecc_pend
  [29] fcc_lut0_ram1_ramecc_enable_clr — Interrupt Enable Clear Register for fcc_lut0_ram1_ramecc_pend
  [28] fcc_lut0_ram0_ramecc_enable_clr — Interrupt Enable Clear Register for fcc_lut0_ram0_ramecc_pend
  [27] fcc_cont_lut3_ram1_ramecc_enable_clr — Interrupt Enable Clear Register for fcc_cont_lut3_ram1_ramecc_pend
  [26] fcc_cont_lut3_ram0_ramecc_enable_clr — Interrupt Enable Clear Register for fcc_cont_lut3_ram0_ramecc_pend
  [25] fcc_cont_lut2_ram1_ramecc_enable_clr — Interrupt Enable Clear Register for fcc_cont_lut2_ram1_ramecc_pend
  [24] fcc_cont_lut2_ram0_ramecc_enable_clr — Interrupt Enable Clear Register for fcc_cont_lut2_ram0_ramecc_pend
  [23] fcc_cont_lut1_ram1_ramecc_enable_clr — Interrupt Enable Clear Register for fcc_cont_lut1_ram1_ramecc_pend
  [22] fcc_cont_lut1_ram0_ramecc_enable_clr — Interrupt Enable Clear Register for fcc_cont_lut1_ram0_ramecc_pend
  [21] fcc_hist_ram1_ramecc_enable_clr — Interrupt Enable Clear Register for fcc_hist_ram1_ramecc_pend
  [20] fcc_hist_ram0_ramecc_enable_clr — Interrupt Enable Clear Register for fcc_hist_ram0_ramecc_pend
  [n+12] stat_mem{n}_ramecc_enable_clr (n=0..7) — Interrupt Enable Clear Register for stat_mem{n}_ramecc_pend
  [11] h3a_lut_ram1_ramecc_enable_clr — Interrupt Enable Clear Register for h3a_lut_ram1_ramecc_pend
  [10] h3a_lut_ram0_ramecc_enable_clr — Interrupt Enable Clear Register for h3a_lut_ram0_ramecc_pend
  [9] lsc_ramecc_enable_clr — Interrupt Enable Clear Register for lsc_ramecc_pend
  [8] dpc_lut_ramecc_enable_clr — Interrupt Enable Clear Register for dpc_lut_ramecc_pend
  [7] wdr_lut_ram1_ramecc_enable_clr — Interrupt Enable Clear Register for wdr_lut_ram1_ramecc_pend
  [6] wdr_lut_ram0_ramecc_enable_clr — Interrupt Enable Clear Register for wdr_lut_ram0_ramecc_pend
  [5] lut1_ram1_ramecc_enable_clr — Interrupt Enable Clear Register for lut1_ram1_ramecc_pend
  [4] lut1_ram0_ramecc_enable_clr — Interrupt Enable Clear Register for lut1_ram0_ramecc_pend
  [3] lut2_ram1_ramecc_enable_clr — Interrupt Enable Clear Register for lut2_ram1_ramecc_pend
  [2] lut2_ram0_ramecc_enable_clr — Interrupt Enable Clear Register for lut2_ram0_ramecc_pend
  [1] lut3_ram1_ramecc_enable_clr — Interrupt Enable Clear Register for lut3_ram1_ramecc_pend
  [0] lut3_ram0_ramecc_enable_clr — Interrupt Enable Clear Register for lut3_ram0_ramecc_pend
0xC0 GLBCE_STRENGTH_IR access per field — Strength (Strength of GLBCE) - This Port sets processing Strength. Minimum value is 0, maximum is 255.
  [7:0] VAL rw — 0x00: Video data will not be processed at all, and will go to the output unchanged 0xFF: Maximum strength
0xC0 PWL3_LUT access per field — Very short frame PWL LUT configuration
  fields as PWL1_LUT
0xC0 dru_local_evt_set0 wo — DRU Local Event Set Register
  [n] comp_evt{n} (n=0..31) — Set the Local Event for channel {n}
0xC0 dru_local_evt_set0 wo — DRU Local Event Set Register
  [n] comp_evt{n} (n=0..63) — Set the Local Event for channel {n}
0xC4 sec_enable_clr_reg1 — Interrupt Enable Clear Register 1
  [5] eelut_1_ramecc_enable_clr — Interrupt Enable Clear Register for eelut_1_ramecc_pend
  [4] eelut_0_ramecc_enable_clr — Interrupt Enable Clear Register for eelut_0_ramecc_pend
  [3] lut_1_ramecc_enable_clr — Interrupt Enable Clear Register for lut_1_ramecc_pend
  [2] lut_0_ramecc_enable_clr — Interrupt Enable Clear Register for lut_0_ramecc_pend
  [1] fcc_lut2_ram1_ramecc_enable_clr — Interrupt Enable Clear Register for fcc_lut2_ram1_ramecc_pend
  [0] fcc_lut2_ram0_ramecc_enable_clr — Interrupt Enable Clear Register for fcc_lut2_ram0_ramecc_pend
0xC4 GLBCE_PERCEPT_EN access per field — Enable for GLBCE Perceptual LUT function
  [1] FWD_EN rw — Forward Perceptual LUT enable
  [0] REV_EN rw — Reverse Perceptual LUT enable[
0xC4 PWL3_LUTCLIP access per field — Very short frame PWL LUT output clip value
  [15:0] LUTCLIP rw — LUT clip value
{0xC8+4i} GLBCE_REV_PERCEPT_LUT_{i:02} access per field (i=0..64) — Reverse Perceptual LUT
  [15:0] VAL rw — LUT Value
0xC8 PWL3_OFF1 access per field — Very Short frame Offset 1
  [23:0] OFST00 rw — S24, Offset at pixel 00
0xCC PWL3_OFF2 access per field — Very Short frame Offset 2
  [23:0] OFST01 rw — S24, Offset at pixel 01
0xD0 PWL3_OFF3 access per field — Very Short frame Offset 3
  [23:0] OFST10 rw — S24, Offset at pixel 10
0xD4 PWL3_OFF4 access per field — Very Short frame Offset 4
  [23:0] OFST11 rw — S24, Offset at pixel 11
0xD8 PWL3_WB_gain12 access per field — Very Short Frame white balance gain 1 and 2
  fields as PWL2_WB_gain12
0xDC PWL3_WB_gain34 access per field — Very Short Frame white balance gain 3 and 4
  fields as PWL2_WB_gain34
0xE0 WDRMRG1_CFG access per field — First stage WDR merge configuration
  [14] CFG_WGT_SEL rw — Select source for weight calculation (0:long, 1: short)
  [13:10] CFG_SBIT rw — U4, short exposure image bit shift
  [9:6] CFG_LBIT rw — U4, long exposure image bit shift
  [5:1] CFG_DST rw — U5, down shift value after WDR merge
  [0] CFG_EN rw — enable
0xE4 WDRMRG1_GAIN — First stage WDR merge gain
  [31:16] GSHORT — U16Q15, gain for long frame
  [15:0] GLONG — U16Q15, gain for short frame
0xE8 WDRMRG1_LBLK12 access per field — First stage WDR merge black level 1 and 2 for long frame
  [27:16] LBK01 rw — U12, black level for long frame at pixel 01
  [11:0] LBK00 rw — U12, black level for long frame at pixel 00
0xEC WDRMRG1_LBLK34 access per field — First stage WDR merge black level 3 and 4 for long frame
  [27:16] LBK11 rw — U12, black level for long frame at pixel 11
  [11:0] LBK10 rw — U12, black level for long frame at pixel 10
0xF0 HWA0_prod6_control — Controlling producer socket6 for HWA0
  [26:24] mask_select — define which tdone_mask apply to prod socket 6. tdone_mask[mask_select] applies to prod_socket6
  [8:1] cons_select — consumer select for HWA0 prod socket 6. Used in decrementing count of producer buffer
  [0] prod_en — '1' -> Producer socket 0 enable , '0' Disable
0xF0 WDRMRG1_SBLK12 access per field — First stage WDR merge black level 1 and 2 for short frame
  [27:16] SBK01 rw — U12, black level for short frame at pixel 01
  [11:0] SBK00 rw — U12, black level for short frame at pixel 00
0xF4 WDRMRG1_SBLK34 access per field — First stage WDR merge black level 3 and 4 for short frame
  [27:16] SBK11 rw — U12, black level for short frame at pixel 11
  [11:0] SBK10 rw — U12, black level for short frame at pixel 10
0xF8 WDRMRG1_LWB12 access per field — First stage WDR merge WB gain 1 and 2 for long frame
  [28:16] WB01 rw — U13Q9, WB gain for long frame at pixel 01
  [12:0] WB00 rw — U13Q9, WB gain for long frame at pixel 00
0xFC WDRMRG1_LWB34 access per field — First stage WDR merge WB gain 3 and 4 for long frame
  [28:16] WB11 rw — U13Q9, WB gain for long frame at pixel 11
  [12:0] WB10 rw — U13Q9, WB gain for long frame at pixel 10
{0x100+0x20*i} enable_reg_level_vpac_out_{i}_0 (i=0..5) — Enable Register {8i}
  [24] enable_level_vpac_out_{i}_en_viss0_lse_out_fr_start_evt — Enable Set for level_vpac_out_{i}_en_viss0_lse_out_fr_start_evt
  [23] enable_level_vpac_out_{i}_en_viss0_lse_cal_vp_err — Enable Set for level_vpac_out_{i}_en_viss0_lse_cal_vp_err
  [22] enable_level_vpac_out_{i}_en_viss0_lse_sl2_wr_err — Enable Set for level_vpac_out_{i}_en_viss0_lse_sl2_wr_err
  [21] enable_level_vpac_out_{i}_en_viss0_lse_sl2_rd_err — Enable Set for level_vpac_out_{i}_en_viss0_lse_sl2_rd_err
  [20] enable_level_vpac_out_{i}_en_viss0_lse_fr_done_evt — Enable Set for level_vpac_out_{i}_en_viss0_lse_fr_done_evt
  [19] enable_level_vpac_out_{i}_en_viss0_ee_syncovf_err — Enable Set for level_vpac_out_{i}_en_viss0_ee_syncovf_err
  [18] enable_level_vpac_out_{i}_en_viss0_ee_cfg_err — Enable Set for level_vpac_out_{i}_en_viss0_ee_cfg_err
  [17] enable_level_vpac_out_{i}_en_viss0_fcc_hist_read_err — Enable Set for level_vpac_out_{i}_en_viss0_fcc_hist_read_err
  [16] enable_level_vpac_out_{i}_en_viss0_fcc_outif_ovf_err — Enable Set for level_vpac_out_{i}_en_viss0_fcc_outif_ovf_err
  [15] enable_level_vpac_out_{i}_en_viss0_fcc_cfg_err — Enable Set for level_vpac_out_{i}_en_viss0_fcc_cfg_err
  [14] enable_level_vpac_out_{i}_en_viss0_fcfa_cfg_err — Enable Set for level_vpac_out_{i}_en_viss0_fcfa_cfg_err
  [13] enable_level_vpac_out_{i}_en_viss0_glbce_vp_err — Enable Set for level_vpac_out_{i}_en_viss0_glbce_vp_err
  [12] enable_level_vpac_out_{i}_en_viss0_glbce_vsync_err — Enable Set for level_vpac_out_{i}_en_viss0_glbce_vsync_err
  [11] enable_level_vpac_out_{i}_en_viss0_glbce_hsync_err — Enable Set for level_vpac_out_{i}_en_viss0_glbce_hsync_err
  [10] enable_level_vpac_out_{i}_en_viss0_glbce_filt_done — Enable Set for level_vpac_out_{i}_en_viss0_glbce_filt_done
  [9] enable_level_vpac_out_{i}_en_viss0_glbce_filt_start — Enable Set for level_vpac_out_{i}_en_viss0_glbce_filt_start
  [8] enable_level_vpac_out_{i}_en_viss0_glbce_cfg_err — Enable Set for level_vpac_out_{i}_en_viss0_glbce_cfg_err
  [7] enable_level_vpac_out_{i}_en_viss0_nsf4v_vblank_err — Enable Set for level_vpac_out_{i}_en_viss0_nsf4v_vblank_err
  [6] enable_level_vpac_out_{i}_en_viss0_nsf4v_hblank_err — Enable Set for level_vpac_out_{i}_en_viss0_nsf4v_hblank_err
  [5] enable_level_vpac_out_{i}_en_viss0_nsf4v_linemem_cfg_err — Enable Set for level_vpac_out_{i}_en_viss0_nsf4v_linemem_cfg_err
  [4] enable_level_vpac_out_{i}_en_viss0_rawfe_h3a_buf_ovrflow_pulse — Enable Set for level_vpac_out_{i}_en_viss0_rawfe_h3a_buf_ovrflow_pulse
  [3] enable_level_vpac_out_{i}_en_viss0_rawfe_h3a_pulse — Enable Set for level_vpac_out_{i}_en_viss0_rawfe_h3a_pulse
  [2] enable_level_vpac_out_{i}_en_viss0_rawfe_af_pulse — Enable Set for level_vpac_out_{i}_en_viss0_rawfe_af_pulse
  [1] enable_level_vpac_out_{i}_en_viss0_rawfe_aew_pulse — Enable Set for level_vpac_out_{i}_en_viss0_rawfe_aew_pulse
  [0] enable_level_vpac_out_{i}_en_viss0_rawfe_cfg_err — Enable Set for level_vpac_out_{i}_en_viss0_rawfe_cfg_err
